VERSION ""

NS_ :

BS_:

BU_: BMS

BO_ 663 BMS_HSC1_FrP02: 8 BMS
 SG_ BMSMainRelaySts_h1HSC1 : 54|2@0+ (1,0) [0|3] "" Vector__XXX

BO_ 667 BMS_HSC1_FrP07: 8 BMS
 SG_ BMSChrgrPlugCnctnIO_h1HSC1 : 6|1@0+ (1,0) [0|1] "" Vector__XXX
 SG_ BMSChrgStsIO_h1HSC1 : 7|1@0+ (1,0) [0|1] "" Vector__XXX

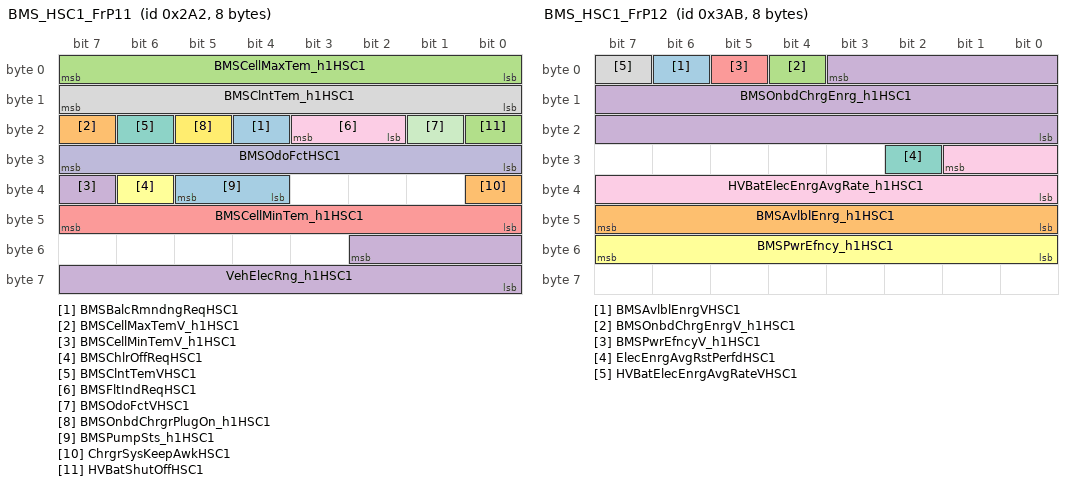
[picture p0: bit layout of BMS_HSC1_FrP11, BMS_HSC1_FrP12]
BO_ 674 BMS_HSC1_FrP11: 8 BMS
 SG_ BMSBalcRmndngReqHSC1 : 20|1@0+ (1,0) [0|1] "" Vector__XXX
 SG_ BMSCellMaxTemV_h1HSC1 : 23|1@0+ (1,0) [0|1] "" Vector__XXX
 SG_ BMSCellMaxTem_h1HSC1 : 7|8@0+ (0.5,-40) [-40|87.5] "DegC" Vector__XXX
 SG_ BMSCellMinTemV_h1HSC1 : 39|1@0+ (1,0) [0|1] "" Vector__XXX
 SG_ BMSCellMinTem_h1HSC1 : 47|8@0+ (0.5,-40) [-40|87.5] "Deg C" Vector__XXX
 SG_ BMSChlrOffReqHSC1 : 38|1@0+ (1,0) [0|1] "" Vector__XXX
 SG_ BMSClntTemVHSC1 : 22|1@0+ (1,0) [0|1] "" Vector__XXX
 SG_ BMSClntTem_h1HSC1 : 15|8@0+ (0.5,-40) [-40|87.5] "degC" Vector__XXX
 SG_ BMSFltIndReqHSC1 : 19|2@0+ (1,0) [0|3] "" Vector__XXX
 SG_ BMSOdoFctHSC1 : 31|8@0+ (0.5,0) [0|127.5] "%" Vector__XXX
 SG_ BMSOdoFctVHSC1 : 17|1@0+ (1,0) [0|1] "" Vector__XXX
 SG_ BMSOnbdChrgrPlugOn_h1HSC1 : 21|1@0+ (1,0) [0|1] "" Vector__XXX
 SG_ BMSPumpSts_h1HSC1 : 37|2@0+ (1,0) [0|3] "" Vector__XXX
 SG_ ChrgrSysKeepAwkHSC1 : 32|1@0+ (1,0) [0|1] "" Vector__XXX
 SG_ HVBatShutOffHSC1 : 16|1@0+ (1,0) [0|1] "" Vector__XXX
 SG_ VehElecRng_h1HSC1 : 50|11@0+ (1,0) [0|2047] "km" Vector__XXX

BO_ 939 BMS_HSC1_FrP12: 8 BMS
 SG_ BMSAvlblEnrgVHSC1 : 6|1@0+ (1,0) [0|1] "" Vector__XXX
 SG_ BMSAvlblEnrg_h1HSC1 : 47|8@0+ (0.1,0) [0|25.5] "kWh" Vector__XXX
 SG_ BMSOnbdChrgEnrgV_h1HSC1 : 4|1@0+ (1,0) [0|1] "" Vector__XXX
 SG_ BMSOnbdChrgEnrg_h1HSC1 : 3|20@0+ (0.1,0) [0|104857] "" Vector__XXX
 SG_ BMSPwrEfncyV_h1HSC1 : 5|1@0+ (1,0) [0|1] "" Vector__XXX
 SG_ BMSPwrEfncy_h1HSC1 : 55|8@0+ (0.5,0) [0|126.5] "" Vector__XXX
 SG_ ElecEnrgAvgRstPerfdHSC1 : 26|1@0+ (1,0) [0|1] "" Vector__XXX
 SG_ HVBatElecEnrgAvgRateVHSC1 : 7|1@0+ (1,0) [0|1] "" Vector__XXX
 SG_ HVBatElecEnrgAvgRate_h1HSC1 : 25|10@0+ (0.1,-20) [-20|82.3] "" Vector__XXX

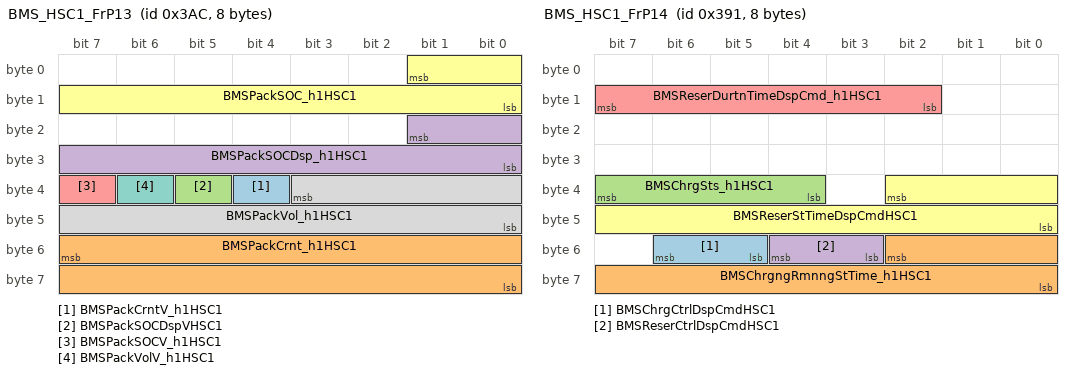
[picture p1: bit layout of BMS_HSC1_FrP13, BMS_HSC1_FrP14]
BO_ 940 BMS_HSC1_FrP13: 8 BMS
 SG_ BMSPackCrntV_h1HSC1 : 36|1@0+ (1,0) [0|1] "" Vector__XXX
 SG_ BMSPackCrnt_h1HSC1 : 55|16@0+ (0.025,-1000) [-1000|638.375] "A" Vector__XXX
 SG_ BMSPackSOCDspVHSC1 : 37|1@0+ (1,0) [0|1] "" Vector__XXX
 SG_ BMSPackSOCDsp_h1HSC1 : 17|10@0+ (0.1,0) [0|102.3] "" Vector__XXX
 SG_ BMSPackSOCV_h1HSC1 : 39|1@0+ (1,0) [0|1] "" Vector__XXX
 SG_ BMSPackSOC_h1HSC1 : 1|10@0+ (0.1,0) [0|102.3] "%" Vector__XXX
 SG_ BMSPackVolV_h1HSC1 : 38|1@0+ (1,0) [0|1] "" Vector__XXX
 SG_ BMSPackVol_h1HSC1 : 35|12@0+ (0.25,0) [0|1023.75] "V" Vector__XXX

BO_ 913 BMS_HSC1_FrP14: 8 BMS
 SG_ BMSChrgCtrlDspCmdHSC1 : 54|2@0+ (1,0) [0|3] "" Vector__XXX
 SG_ BMSChrgngRmnngStTime_h1HSC1 : 50|11@0+ (1,0) [0|1500] "minute" Vector__XXX
 SG_ BMSChrgSts_h1HSC1 : 39|4@0+ (1,0) [0|15] "" Vector__XXX
 SG_ BMSReserCtrlDspCmdHSC1 : 52|2@0+ (1,0) [0|3] "" Vector__XXX
 SG_ BMSReserDurtnTimeDspCmd_h1HSC1 : 15|6@0+ (0.5,0) [0|20] "" Vector__XXX
 SG_ BMSReserStTimeDspCmdHSC1 : 34|11@0+ (1,0) [0|2047] "" Vector__XXX

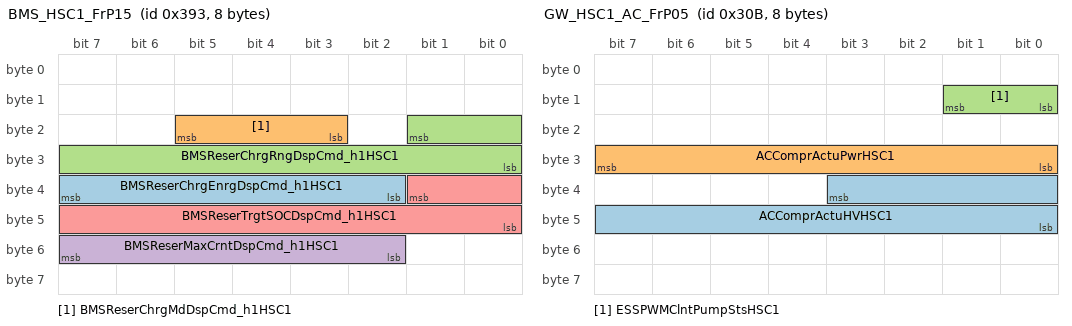
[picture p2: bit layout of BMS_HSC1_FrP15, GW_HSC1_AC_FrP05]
BO_ 915 BMS_HSC1_FrP15: 8 BMS
 SG_ BMSReserChrgEnrgDspCmd_h1HSC1 : 39|6@0+ (1,0) [0|63] "" Vector__XXX
 SG_ BMSReserChrgMdDspCmd_h1HSC1 : 21|3@0+ (1,0) [0|7] "" Vector__XXX
 SG_ BMSReserChrgRngDspCmd_h1HSC1 : 17|10@0+ (1,0) [0|1023] "" Vector__XXX
 SG_ BMSReserMaxCrntDspCmd_h1HSC1 : 55|6@0+ (1,0) [0|32] "" Vector__XXX
 SG_ BMSReserTrgtSOCDspCmd_h1HSC1 : 33|10@0+ (0.1,0) [0|102.3] "" Vector__XXX

BO_ 936 BMS_HSC1_FrP16: 8 BMS
 SG_ ChrgngRmnngTimeV_h1HSC1 : 54|1@0+ (1,0) [0|1] "" Vector__XXX
 SG_ ChrgngRmnngTime_h1HSC1 : 31|10@0+ (1,0) [0|1023] "minute" Vector__XXX

BO_ 1288 BMS_HSC1_FrP18: 8 BMS
 SG_ BMSEmsnRltdMalfAHSC1 : 7|1@0+ (1,0) [0|1] "" Vector__XXX

BO_ 1803 DIAG_DTCInfo_BMS: 7 BMS
 SG_ DTCInfomationBMSHSC1 : 7|56@0+ (1,0) [0|0] "" Vector__XXX

BO_ 2015 DIAG_FuncReq_HSC1: 8 Vector__XXX
 SG_ DiagnosticFuncAddrReq : 7|64@0+ (1,0) [0|0] ""  BMS

BO_ 1921 DIAG_PhysReq_BMS: 8 Vector__XXX
 SG_ DiagnosticReqBMS_h1 : 7|64@0+ (1,0) [0|0] ""  BMS

BO_ 1929 DIAG_PhysResp_BMS: 8 BMS
 SG_ DiagnosticRespBMS : 7|64@0+ (1,0) [0|0] "" Vector__XXX

BO_ 201 ECM_HSC1_FrP00: 8 Vector__XXX
 SG_ EnRunAHSC1 : 7|1@0+ (1,0) [0|1] ""  BMS
 SG_ EnSpdHSC1 : 15|16@0+ (0.25,0) [0|16383.8] "rpm"  BMS

BO_ 404 ECM_HSC1_FrP04: 8 Vector__XXX
 SG_ TrShftLvrPosHSC1 : 27|4@0+ (1,0) [0|15] ""  BMS
 SG_ TrShftLvrPosVHSC1 : 28|1@0+ (1,0) [0|1] ""  BMS

BO_ 1217 ECM_HSC1_FrP14: 8 Vector__XXX
 SG_ EnClntTemHSC1 : 23|8@0+ (1,-40) [-40|215] "deg C"  BMS
 SG_ EnClntTemVHSC1 : 6|1@0+ (1,0) [0|1] ""  BMS

BO_ 889 GW_HSC1_AC_FrP02: 8 Vector__XXX
 SG_ ACAmbtTemHSC1 : 7|8@0+ (0.5,-40) [-40|87.5] "deg C"  BMS
 SG_ ACAmbtTemVHSC1 : 39|1@0+ (1,0) [0|1] ""  BMS

BO_ 868 GW_HSC1_AC_FrP03: 8 Vector__XXX
 SG_ ACComprReqHSC1 : 17|2@0+ (1,0) [0|3] ""  BMS
 SG_ HVBatCoolngSysEnbdHSC1 : 55|1@0+ (1,0) [0|1] ""  BMS

BO_ 779 GW_HSC1_AC_FrP05: 8 Vector__XXX
 SG_ ACComprActuHVHSC1 : 35|12@0+ (0.25,0) [0|1023.25] ""  BMS
 SG_ ACComprActuPwrHSC1 : 31|8@0+ (0.03,0) [0|7.65] "Kw"  BMS
 SG_ ESSPWMClntPumpStsHSC1 : 9|2@0+ (1,0) [0|3] ""  BMS

BO_ 1130 GW_HSC1_BCM_FrP04: 8 Vector__XXX
 SG_ BntOpenStsHSC1 : 47|2@0+ (1,0) [0|3] ""  BMS
 SG_ VehLckngStaHSC1 : 22|3@0+ (1,0) [0|7] ""  BMS

BO_ 540 GW_HSC1_BCM_FrP06: 8 Vector__XXX
 SG_ RVSReqHSC1 : 34|1@0+ (1,0) [0|1] ""  BMS

BO_ 498 GW_HSC1_BCM_FrP07: 2 Vector__XXX
 SG_ SysBPMHSC1 : 5|2@0+ (1,0) [0|3] ""  BMS
 SG_ SysBPMEnbdHSC1 : 6|1@0+ (1,0) [0|1] ""  BMS

BO_ 886 GW_HSC1_FICM_FrP02: 8 Vector__XXX
 SG_ RstrFctryDeftsReqHSC1 : 56|1@0+ (1,0) [0|1] ""  BMS

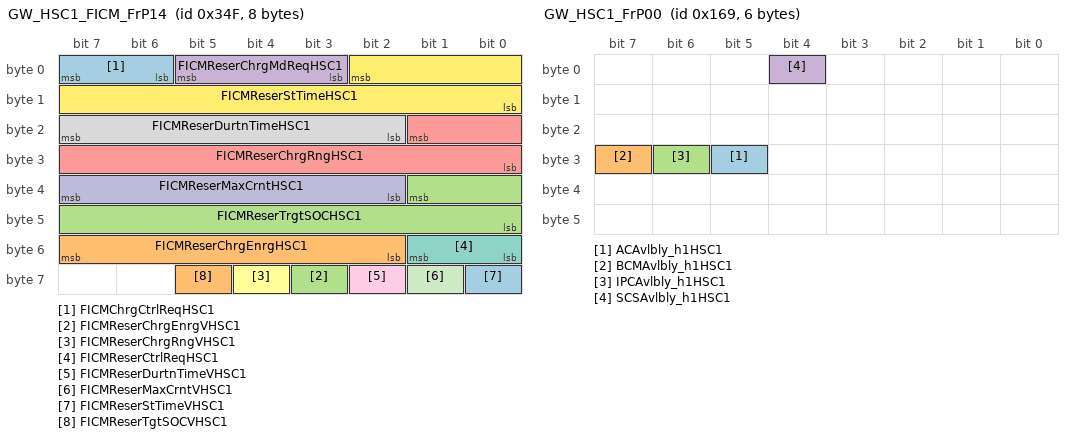
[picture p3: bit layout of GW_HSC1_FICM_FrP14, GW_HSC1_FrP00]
BO_ 847 GW_HSC1_FICM_FrP14: 8 Vector__XXX
 SG_ FICMChrgCtrlReqHSC1 : 7|2@0+ (1,0) [0|3] ""  BMS
 SG_ FICMReserChrgEnrgHSC1 : 55|6@0+ (1,0) [0|63] ""  BMS
 SG_ FICMReserChrgEnrgVHSC1 : 59|1@0+ (1,0) [0|1] ""  BMS
 SG_ FICMReserChrgMdReqHSC1 : 5|3@0+ (1,0) [0|7] ""  BMS
 SG_ FICMReserChrgRngHSC1 : 17|10@0+ (1,0) [0|1023] ""  BMS
 SG_ FICMReserChrgRngVHSC1 : 60|1@0+ (1,0) [0|1] ""  BMS
 SG_ FICMReserCtrlReqHSC1 : 49|2@0+ (1,0) [0|3] ""  BMS
 SG_ FICMReserDurtnTimeHSC1 : 23|6@0+ (0.5,0) [0|20] ""  BMS
 SG_ FICMReserDurtnTimeVHSC1 : 58|1@0+ (1,0) [0|1] ""  BMS
 SG_ FICMReserMaxCrntHSC1 : 39|6@0+ (1,0) [0|32] ""  BMS
 SG_ FICMReserMaxCrntVHSC1 : 57|1@0+ (1,0) [0|1] ""  BMS
 SG_ FICMReserStTimeHSC1 : 2|11@0+ (1,0) [0|2047] ""  BMS
 SG_ FICMReserStTimeVHSC1 : 56|1@0+ (1,0) [0|1] ""  BMS
 SG_ FICMReserTgtSOCVHSC1 : 61|1@0+ (1,0) [0|1] ""  BMS
 SG_ FICMReserTrgtSOCHSC1 : 33|10@0+ (0.1,0) [0|102.3] ""  BMS

BO_ 361 GW_HSC1_FrP00: 6 Vector__XXX
 SG_ ACAvlbly_h1HSC1 : 29|1@0+ (1,0) [0|1] ""  BMS
 SG_ BCMAvlbly_h1HSC1 : 31|1@0+ (1,0) [0|1] ""  BMS
 SG_ IPCAvlbly_h1HSC1 : 30|1@0+ (1,0) [0|1] ""  BMS
 SG_ SCSAvlbly_h1HSC1 : 4|1@0+ (1,0) [0|1] ""  BMS

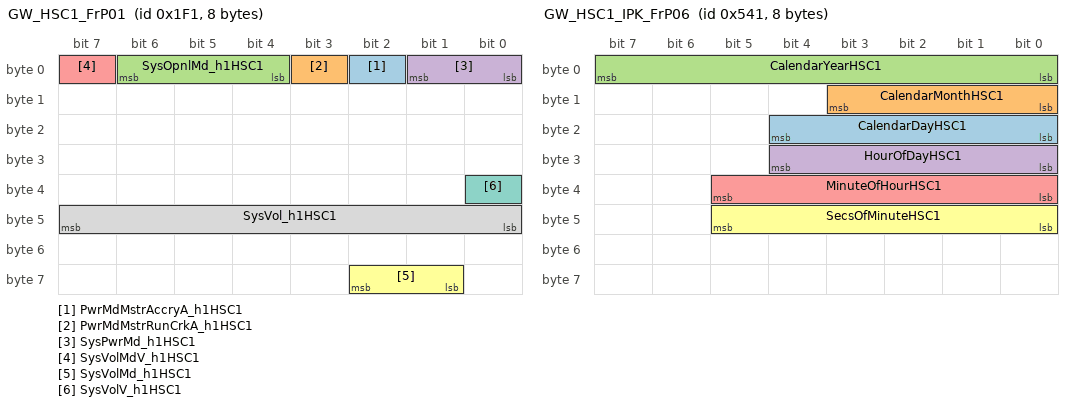
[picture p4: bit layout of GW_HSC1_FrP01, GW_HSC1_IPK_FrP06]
BO_ 497 GW_HSC1_FrP01: 8 Vector__XXX
 SG_ PwrMdMstrAccryA_h1HSC1 : 2|1@0+ (1,0) [0|1] ""  BMS
 SG_ PwrMdMstrRunCrkA_h1HSC1 : 3|1@0+ (1,0) [0|1] ""  BMS
 SG_ SysOpnlMd_h1HSC1 : 6|3@0+ (1,0) [0|7] ""  BMS
 SG_ SysPwrMd_h1HSC1 : 1|2@0+ (1,0) [0|3] ""  BMS
 SG_ SysVolMdV_h1HSC1 : 7|1@0+ (1,0) [0|1] ""  BMS
 SG_ SysVolMd_h1HSC1 : 58|2@0+ (1,0) [0|3] ""  BMS
 SG_ SysVolV_h1HSC1 : 32|1@0+ (1,0) [0|1] ""  BMS
 SG_ SysVol_h1HSC1 : 47|8@0+ (0.1,3) [3|28.5] "V"  BMS

BO_ 1344 GW_HSC1_FrP07: 8 Vector__XXX
 SG_ VehOdoV_h1HSC1 : 31|1@0+ (1,0) [0|1] ""  BMS
 SG_ VehOdo_h1HSC1 : 7|24@0+ (1,0) [0|16777200] ""  BMS

BO_ 1009 GW_HSC1_FrP10: 8 Vector__XXX
 SG_ OtsdAirTemCrValV_h1HSC1 : 48|1@0+ (1,0) [0|1] ""  BMS
 SG_ OtsdAirTemCrVal_h1HSC1 : 63|8@0+ (0.5,-40) [-40|87.5] "deg C"  BMS

BO_ 1345 GW_HSC1_IPK_FrP06: 8 Vector__XXX
 SG_ CalendarDayHSC1 : 20|5@0+ (1,0) [0|31] "day"  BMS
 SG_ CalendarMonthHSC1 : 11|4@0+ (1,0) [0|15] ""  BMS
 SG_ CalendarYearHSC1 : 7|8@0+ (1,2000) [2000|2255] "year"  BMS
 SG_ HourOfDayHSC1 : 28|5@0+ (1,0) [0|23] ""  BMS
 SG_ MinuteOfHourHSC1 : 37|6@0+ (1,0) [0|59] ""  BMS
 SG_ SecsOfMinuteHSC1 : 45|6@0+ (1,0) [0|59] ""  BMS

BO_ 835 GW_HSC1_IPK_FrP10: 8 Vector__XXX
 SG_ ElecEnrgAvgRstReqHSC1 : 7|1@0+ (1,0) [0|1] ""  BMS

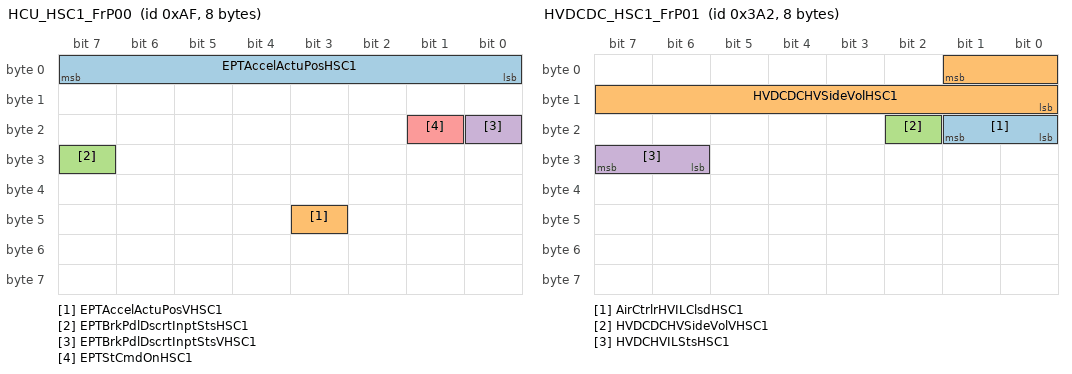
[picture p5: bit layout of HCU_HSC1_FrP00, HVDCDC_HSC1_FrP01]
BO_ 175 HCU_HSC1_FrP00: 8 Vector__XXX
 SG_ EPTAccelActuPosHSC1 : 7|8@0+ (0.392157,0) [0|100] "%"  BMS
 SG_ EPTAccelActuPosVHSC1 : 43|1@0+ (1,0) [0|1] ""  BMS
 SG_ EPTBrkPdlDscrtInptStsHSC1 : 31|1@0+ (1,0) [0|1] ""  BMS
 SG_ EPTBrkPdlDscrtInptStsVHSC1 : 16|1@0+ (1,0) [0|1] ""  BMS
 SG_ EPTStCmdOnHSC1 : 17|1@0+ (1,0) [0|1] ""  BMS

BO_ 406 HCU_HSC1_FrP01: 8 Vector__XXX
 SG_ EPTRdyHSC1 : 38|1@0+ (1,0) [0|1] ""  BMS

BO_ 907 HCU_HSC1_FrP07: 8 Vector__XXX
 SG_ ElecVehSysMdHSC1 : 55|4@0+ (1,0) [0|15] ""  BMS
 SG_ EPTDrvngMdSwStsHSC1 : 18|3@0+ (1,0) [0|7] ""  BMS

BO_ 930 HVDCDC_HSC1_FrP01: 8 Vector__XXX
 SG_ AirCtrlrHVILClsdHSC1 : 17|2@0+ (1,0) [0|3] ""  BMS
 SG_ HVDCDCHVSideVolHSC1 : 1|10@0+ (1,0) [0|1023] "V"  BMS
 SG_ HVDCDCHVSideVolVHSC1 : 18|1@0+ (1,0) [0|1] ""  BMS
 SG_ HVDCHVILStsHSC1 : 31|2@0+ (1,0) [0|3] ""  BMS

BO_ 147 ISC_HSC1_FrP03: 8 Vector__XXX
 SG_ ISGSpd_h1HSC1 : 23|16@0+ (1,-32768) [-32768|32767] "rpm"  BMS

BO_ 851 SCS_HSC1_FrP15: 8 Vector__XXX
 SG_ VehSpdAvgDrvnV_h1HSC1 : 7|1@0+ (1,0) [0|1] ""  BMS
 SG_ VehSpdAvgDrvn_h1HSC1 : 6|15@0+ (0.015625,0) [0|511.984] "km/h"  BMS

BO_ 355 SDM_HSC1_FrP00: 8 Vector__XXX
 SG_ AirbagDplHSC1 : 11|1@0+ (1,0) [0|1] ""  BMS

CM_ SG_ 663 BMSMainRelaySts_h1HSC1 "Battery Management System Main Relay Status";
CM_ SG_ 667 BMSChrgrPlugCnctnIO_h1HSC1 "Battery Management System Charger Plug Connection Indication On";
CM_ SG_ 667 BMSChrgStsIO_h1HSC1 "Battery Management System Charge Status Indication On";
CM_ SG_ 674 BMSBalcRmndngReqHSC1 "Battery Management System Balance Reminding Request
";
CM_ SG_ 674 BMSCellMaxTemV_h1HSC1 "Battery Management System Cell Maximum Temperature Validity
";
CM_ SG_ 674 BMSCellMaxTem_h1HSC1 "Battery Management System Cell Maximum Temperature
";
CM_ SG_ 674 BMSCellMinTemV_h1HSC1 "Battery Management System Cell Minimum Temperature Validity";
CM_ SG_ 674 BMSCellMinTem_h1HSC1 "Battery Management System Cell Minimum Temperature";
CM_ SG_ 674 BMSChlrOffReqHSC1 "Battery Management System Chiller Off Request";
CM_ SG_ 674 BMSClntTemVHSC1 "Battery Management System Coolant Temperature Validity";
CM_ SG_ 674 BMSClntTem_h1HSC1 "Battery Management System Coolant Temperature";
CM_ SG_ 674 BMSFltIndReqHSC1 "Battery Management System Fault Indication Request
";
CM_ SG_ 674 BMSOdoFctHSC1 "Battery Management System Odometer Factor
";
CM_ SG_ 674 BMSOdoFctVHSC1 "Battery Management System Odometer Factor Validity
";
CM_ SG_ 674 BMSOnbdChrgrPlugOn_h1HSC1 "Battery Management System Onboard Charger Plug On";
CM_ SG_ 674 BMSPumpSts_h1HSC1 "Battery Management System Pump Status";
CM_ SG_ 674 ChrgrSysKeepAwkHSC1 "Charger System Keep Awake";
CM_ SG_ 674 HVBatShutOffHSC1 "High Voltage Battery Shut Off";
CM_ SG_ 674 VehElecRng_h1HSC1 "Vehicle Electric Range";
CM_ SG_ 939 BMSAvlblEnrgVHSC1 "Battery Management System Available Energy Validity";
CM_ SG_ 939 BMSAvlblEnrg_h1HSC1 "Battery Management System Available Energy";
CM_ SG_ 939 BMSOnbdChrgEnrgV_h1HSC1 "Battery Management System Onboard Charge Energy Validity
";
CM_ SG_ 939 BMSOnbdChrgEnrg_h1HSC1 "Battery Management System Onboard Charge Energy
";
CM_ SG_ 939 BMSPwrEfncyV_h1HSC1 "Battery Management System Power Efficiency Validity";
CM_ SG_ 939 BMSPwrEfncy_h1HSC1 "Battery Management System Power Efficiency";
CM_ SG_ 939 ElecEnrgAvgRstPerfdHSC1 "Electric Energy Average Reset Performed";
CM_ SG_ 939 HVBatElecEnrgAvgRateVHSC1 "High Voltage Battery Electric Energy Average Rate Validity";
CM_ SG_ 939 HVBatElecEnrgAvgRate_h1HSC1 "High Voltage Battery Electric Energy Average Rate";
CM_ SG_ 940 BMSPackCrntV_h1HSC1 "Battery Management System Pack Current Validity";
CM_ SG_ 940 BMSPackCrnt_h1HSC1 "Battery Management System Pack Current";
CM_ SG_ 940 BMSPackSOCDspVHSC1 "Battery Management System Pack State Of Charge Display Validity";
CM_ SG_ 940 BMSPackSOCDsp_h1HSC1 "SOC displayed for customer";
CM_ SG_ 940 BMSPackSOCV_h1HSC1 "Battery Management System Pack State Of Charge Validity
";
CM_ SG_ 940 BMSPackSOC_h1HSC1 "Battery Management System Pack State Of Charge
";
CM_ SG_ 940 BMSPackVolV_h1HSC1 "Battery Management System Pack Voltage Validity";
CM_ SG_ 940 BMSPackVol_h1HSC1 "Battery Management System Pack Voltage";
CM_ SG_ 913 BMSChrgCtrlDspCmdHSC1 "Battery Management System Charge Control Display Command";
CM_ SG_ 913 BMSChrgngRmnngStTime_h1HSC1 "Battery Management System Charging Remain Start Time";
CM_ SG_ 913 BMSChrgSts_h1HSC1 "Battery Management System Charge Status";
CM_ SG_ 913 BMSReserCtrlDspCmdHSC1 "Battery Management System Reservation Control Display Command";
CM_ SG_ 913 BMSReserDurtnTimeDspCmd_h1HSC1 "Battery Management System Reservation Duration Time Display Command";
CM_ SG_ 913 BMSReserStTimeDspCmdHSC1 "Battery Management System Reservation Start Time Display Command";
CM_ SG_ 915 BMSReserChrgEnrgDspCmd_h1HSC1 "Battery Management System Reservation Charge Energy Display Command";
CM_ SG_ 915 BMSReserChrgMdDspCmd_h1HSC1 "Battery Management System Reservation Charge Mode Display Command";
CM_ SG_ 915 BMSReserChrgRngDspCmd_h1HSC1 "Battery Management System Reservation Charge Range Display Command";
CM_ SG_ 915 BMSReserMaxCrntDspCmd_h1HSC1 "Battery Management System Reservation Maximun Current Display Command";
CM_ SG_ 915 BMSReserTrgtSOCDspCmd_h1HSC1 "Battery Management System Reservaion Target Soc Display Command";
CM_ SG_ 936 ChrgngRmnngTimeV_h1HSC1 "Charging Remaining Time Validity";
CM_ SG_ 936 ChrgngRmnngTime_h1HSC1 "Charging Remaining Time";
CM_ SG_ 1288 BMSEmsnRltdMalfAHSC1 "Battery Management System Emissions Related Malfunction Active";
CM_ SG_ 2015 DiagnosticFuncAddrReq "Diagnostic functional address request";
CM_ SG_ 1921 DiagnosticReqBMS_h1 "Diagnostic request to BMS";
CM_ SG_ 1929 DiagnosticRespBMS "Diagnostic response from BMS";
CM_ SG_ 201 EnRunAHSC1 "Engine Run Active";
CM_ SG_ 201 EnSpdHSC1 "Engine Speed";
CM_ SG_ 404 TrShftLvrPosHSC1 "Transmission Shift Lever Position

For DCT/AT transmission :
$0=Between Ranges
$1=Park Range
$2=Reverse Range
$3=Neutral Range
$4=Forward Range A
$5=Forward Range B
$6=Forward Range C
$7=Forward Range D
$8=Forward Range E
$9=Forward Range F
$A=Forward Range G
$B=Forward Range H
$F=Lever Position Unknown

For Manual Transmission: only below status are used
$2=Reverse Range
$3=Neutral Range (Validity on MT vehicles is only protected for Neutral range)
$F=Lever Position Unknown";
CM_ SG_ 404 TrShftLvrPosVHSC1 "Transmission Shift Lever Position Validity";
CM_ SG_ 1217 EnClntTemHSC1 "Engine Coolant Temperature";
CM_ SG_ 1217 EnClntTemVHSC1 "Engine Coolant Temperature Validity";
CM_ SG_ 889 ACAmbtTemHSC1 "Air Conditioning Ambient Temperature";
CM_ SG_ 889 ACAmbtTemVHSC1 "Air Conditioning Ambient Temperature Validity";
CM_ SG_ 868 ACComprReqHSC1 "Air Conditioning Compressor Request";
CM_ SG_ 868 HVBatCoolngSysEnbdHSC1 "High Voltage Battery Cooling System Enabled
";
CM_ SG_ 779 ACComprActuHVHSC1 "Air Conditioning Compressor Actual High Voltage
";
CM_ SG_ 779 ACComprActuPwrHSC1 "Air Conditioning Compressor Actual Power
";
CM_ SG_ 779 ESSPWMClntPumpStsHSC1 "Energy Storage System Pulse Width Modulation Coolant Pump Status";
CM_ SG_ 1130 BntOpenStsHSC1 "Bonnet Open Status";
CM_ SG_ 1130 VehLckngStaHSC1 "Vehicle Locking State";
CM_ SG_ 540 RVSReqHSC1 "Remote Vehicle Start Request";
CM_ SG_ 498 SysBPMHSC1 "System Backup Power Mode";
CM_ SG_ 498 SysBPMEnbdHSC1 "System Backup Power Mode Enabled";
CM_ SG_ 886 RstrFctryDeftsReqHSC1 "Restore Factory Defaults Request";
CM_ SG_ 847 FICMChrgCtrlReqHSC1 "Front Infotainment Control Module Charge Control Request";
CM_ SG_ 847 FICMReserChrgEnrgHSC1 "Front Infotainment Control Module Reservation Charge Energy";
CM_ SG_ 847 FICMReserChrgEnrgVHSC1 "Front Infotainment Control Module Reservation Charge Energy Validity";
CM_ SG_ 847 FICMReserChrgMdReqHSC1 "Front Infotainment Control Module Reservation Charge Mode Request";
CM_ SG_ 847 FICMReserChrgRngHSC1 "Front Infotainment Control Module Reservation Charge Range";
CM_ SG_ 847 FICMReserChrgRngVHSC1 "Front Infotainment Control Module Reservation Charge Range Validity";
CM_ SG_ 847 FICMReserCtrlReqHSC1 "Front Infotainment Control Module Reservation Control Request";
CM_ SG_ 847 FICMReserDurtnTimeHSC1 "Front Infotainment Control Module Reservation Duration Time";
CM_ SG_ 847 FICMReserDurtnTimeVHSC1 "Front Infotainment Control Module Reservation Duration Time Validity";
CM_ SG_ 847 FICMReserMaxCrntHSC1 "Front Infotainment Control Module Reservation Maximun Current Request";
CM_ SG_ 847 FICMReserMaxCrntVHSC1 "Front Infotainment Control Module Reservation Maximun Current Request Validity";
CM_ SG_ 847 FICMReserStTimeHSC1 "Front Infotainment Control Module Reservation Start Time";
CM_ SG_ 847 FICMReserStTimeVHSC1 "Front Infotainment Control Module Reservation Start Time Validity";
CM_ SG_ 847 FICMReserTgtSOCVHSC1 "Front Infotainment Control Module Reservation Target Soc Validity";
CM_ SG_ 847 FICMReserTrgtSOCHSC1 "Front Infotainment Control Module Reservation Target Soc";
CM_ SG_ 361 ACAvlbly_h1HSC1 "AC Available

Detect if specific ECU is available according to node missing strategy by gateway ECU.

";
CM_ SG_ 361 BCMAvlbly_h1HSC1 "BCM Available

Detect if specific ECU is available according to node missing strategy by gateway ECU.
";
CM_ SG_ 361 IPCAvlbly_h1HSC1 "IPK Available

Detect if specific ECU is available according to node missing strategy by gateway ECU.

";
CM_ SG_ 361 SCSAvlbly_h1HSC1 "SCS Available

Detect if specific ECU is available according to node missing strategy by gateway ECU.

";
CM_ SG_ 497 PwrMdMstrAccryA_h1HSC1 "Power Mode Master Accessory Terminal Status";
CM_ SG_ 497 PwrMdMstrRunCrkA_h1HSC1 "Power Mode Master Run Crank Terminal Status";
CM_ SG_ 497 SysOpnlMd_h1HSC1 "System Operational Mode";
CM_ SG_ 497 SysPwrMd_h1HSC1 "System Power Mode";
CM_ SG_ 497 SysVolMdV_h1HSC1 "System Voltage Mode Validity ";
CM_ SG_ 497 SysVolMd_h1HSC1 "System Voltage Mode ";
CM_ SG_ 497 SysVolV_h1HSC1 "Battery Voltage Validity";
CM_ SG_ 497 SysVol_h1HSC1 "Battery Voltage";
CM_ SG_ 1344 VehOdoV_h1HSC1 "Vehicle Odometer Validity";
CM_ SG_ 1344 VehOdo_h1HSC1 "Vehicle Odometer";
CM_ SG_ 1009 OtsdAirTemCrValV_h1HSC1 "Outside Air Temperature Corrected Value Validity";
CM_ SG_ 1009 OtsdAirTemCrVal_h1HSC1 "Outside Air Temperature Corrected Value";
CM_ SG_ 1345 CalendarDayHSC1 "current day info.";
CM_ SG_ 1345 CalendarMonthHSC1 "current month info.";
CM_ SG_ 1345 CalendarYearHSC1 "current year info";
CM_ SG_ 1345 HourOfDayHSC1 "Hour Of Day.
current Hour info.";
CM_ SG_ 1345 MinuteOfHourHSC1 "Minute Of Hour.
current Minute info.";
CM_ SG_ 1345 SecsOfMinuteHSC1 "Seconds Of Minute
current Second info.";
CM_ SG_ 835 ElecEnrgAvgRstReqHSC1 "Electric Energy Average Reset Request";
CM_ SG_ 175 EPTAccelActuPosHSC1 "Electric Powertrain Accelerator Actual Position";
CM_ SG_ 175 EPTAccelActuPosVHSC1 "Electric Powertrain Accelerator Actual Position Validity";
CM_ SG_ 175 EPTBrkPdlDscrtInptStsHSC1 "Electric Powertrain Brake Pedal Discrete Input Status";
CM_ SG_ 175 EPTBrkPdlDscrtInptStsVHSC1 "Electric Powertrain Brake Pedal Discrete Input Status Validity";
CM_ SG_ 175 EPTStCmdOnHSC1 "Electric Powertrain Start Command On";
CM_ SG_ 406 EPTRdyHSC1 "Electric Powertrain Ready";
CM_ SG_ 907 ElecVehSysMdHSC1 "Electric Vehicle System Mode
";
CM_ SG_ 907 EPTDrvngMdSwStsHSC1 "Electric Powertrain Driving Mode Switch Status";
CM_ SG_ 930 AirCtrlrHVILClsdHSC1 "Air Controller High Voltage Interlock Loop Closed";
CM_ SG_ 930 HVDCDCHVSideVolHSC1 "High Voltage Direct Current Direct Current High Voltage Side Voltage";
CM_ SG_ 930 HVDCDCHVSideVolVHSC1 "High Voltage Direct Current Direct Current High Voltage Side Voltage Validity";
CM_ SG_ 930 HVDCHVILStsHSC1 "High Voltage Direct Current High Voltage Interlock Loop Status";
CM_ SG_ 147 ISGSpd_h1HSC1 "Integrated Starter Generator Speed";
CM_ SG_ 851 VehSpdAvgDrvnV_h1HSC1 "Vehicle Speed Average Driven Validity";
CM_ SG_ 851 VehSpdAvgDrvn_h1HSC1 "Vehicle Speed Average Driven";
CM_ SG_ 355 AirbagDplHSC1 "Airbag Deployed";
BA_DEF_  "BusType" STRING ;
BA_DEF_ SG_  "GenSigLongName" STRING ;
BA_DEF_ SG_  "GenSigStartValue" INT -9.22337203685478E+018 1.84467440737096E+019;
BA_DEF_ BO_  "GenMsgDelayTime" FLOAT 0 300000;
BA_DEF_ BO_  "GenMsgCycleTime" FLOAT 0 300000;
BA_DEF_ BO_  "GenMsgSendType" ENUM  "cyclic","spontaneous","cyclicIfActive","spontaneousWithDelay","immediate";
BA_DEF_DEF_  "BusType" "";
BA_DEF_DEF_  "GenSigLongName" "";
BA_DEF_DEF_  "GenSigStartValue" 0;
BA_DEF_DEF_  "GenMsgDelayTime" 0;
BA_DEF_DEF_  "GenMsgCycleTime" 0;
BA_DEF_DEF_  "GenMsgSendType" "";
BA_ "BusType" "CAN";
BA_ "GenMsgCycleTime" BO_ 663 50;
BA_ "GenMsgSendType" BO_ 663 0;
BA_ "GenMsgCycleTime" BO_ 667 50;
BA_ "GenMsgSendType" BO_ 667 0;
BA_ "GenMsgCycleTime" BO_ 674 100;
BA_ "GenMsgSendType" BO_ 674 0;
BA_ "GenMsgCycleTime" BO_ 939 100;
BA_ "GenMsgSendType" BO_ 939 0;
BA_ "GenMsgCycleTime" BO_ 940 100;
BA_ "GenMsgSendType" BO_ 940 0;
BA_ "GenMsgCycleTime" BO_ 913 100;
BA_ "GenMsgSendType" BO_ 913 0;
BA_ "GenMsgCycleTime" BO_ 915 100;
BA_ "GenMsgSendType" BO_ 915 0;
BA_ "GenMsgCycleTime" BO_ 936 100;
BA_ "GenMsgSendType" BO_ 936 0;
BA_ "GenMsgCycleTime" BO_ 1288 500;
BA_ "GenMsgSendType" BO_ 1288 0;
BA_ "GenMsgSendType" BO_ 1803 1;
BA_ "GenMsgSendType" BO_ 2015 4;
BA_ "GenMsgSendType" BO_ 1921 4;
BA_ "GenMsgSendType" BO_ 1929 4;
BA_ "GenMsgCycleTime" BO_ 201 10;
BA_ "GenMsgSendType" BO_ 201 0;
BA_ "GenMsgCycleTime" BO_ 404 25;
BA_ "GenMsgSendType" BO_ 404 0;
BA_ "GenMsgCycleTime" BO_ 1217 500;
BA_ "GenMsgSendType" BO_ 1217 0;
BA_ "GenMsgCycleTime" BO_ 889 100;
BA_ "GenMsgSendType" BO_ 889 0;
BA_ "GenMsgCycleTime" BO_ 868 100;
BA_ "GenMsgSendType" BO_ 868 0;
BA_ "GenMsgCycleTime" BO_ 779 100;
BA_ "GenMsgSendType" BO_ 779 0;
BA_ "GenMsgCycleTime" BO_ 1130 50;
BA_ "GenMsgSendType" BO_ 1130 0;
BA_ "GenMsgCycleTime" BO_ 540 50;
BA_ "GenMsgSendType" BO_ 540 0;
BA_ "GenMsgCycleTime" BO_ 498 20;
BA_ "GenMsgSendType" BO_ 498 0;
BA_ "GenMsgCycleTime" BO_ 886 100;
BA_ "GenMsgSendType" BO_ 886 0;
BA_ "GenMsgCycleTime" BO_ 847 100;
BA_ "GenMsgSendType" BO_ 847 0;
BA_ "GenMsgCycleTime" BO_ 361 20;
BA_ "GenMsgSendType" BO_ 361 0;
BA_ "GenMsgCycleTime" BO_ 497 20;
BA_ "GenMsgSendType" BO_ 497 0;
BA_ "GenMsgCycleTime" BO_ 1344 1000;
BA_ "GenMsgSendType" BO_ 1344 0;
BA_ "GenMsgCycleTime" BO_ 1009 250;
BA_ "GenMsgSendType" BO_ 1009 0;
BA_ "GenMsgCycleTime" BO_ 1345 200;
BA_ "GenMsgSendType" BO_ 1345 0;
BA_ "GenMsgCycleTime" BO_ 835 100;
BA_ "GenMsgSendType" BO_ 835 0;
BA_ "GenMsgCycleTime" BO_ 175 10;
BA_ "GenMsgSendType" BO_ 175 0;
BA_ "GenMsgCycleTime" BO_ 406 20;
BA_ "GenMsgSendType" BO_ 406 0;
BA_ "GenMsgCycleTime" BO_ 907 100;
BA_ "GenMsgSendType" BO_ 907 0;
BA_ "GenMsgCycleTime" BO_ 930 100;
BA_ "GenMsgSendType" BO_ 930 0;
BA_ "GenMsgCycleTime" BO_ 147 10;
BA_ "GenMsgSendType" BO_ 147 0;
BA_ "GenMsgCycleTime" BO_ 851 100;
BA_ "GenMsgSendType" BO_ 851 0;
BA_ "GenMsgCycleTime" BO_ 355 20;
BA_ "GenMsgSendType" BO_ 355 0;
BA_ "GenSigStartValue" SG_ 667 BMSChrgrPlugCnctnIO_h1HSC1 1;
BA_ "GenSigStartValue" SG_ 667 BMSChrgStsIO_h1HSC1 1;
BA_ "GenSigStartValue" SG_ 674 BMSCellMaxTemV_h1HSC1 1;
BA_ "GenSigStartValue" SG_ 674 BMSCellMaxTem_h1HSC1 255;
BA_ "GenSigStartValue" SG_ 674 BMSCellMinTemV_h1HSC1 1;
BA_ "GenSigStartValue" SG_ 674 BMSCellMinTem_h1HSC1 255;
BA_ "GenSigStartValue" SG_ 674 BMSClntTemVHSC1 1;
BA_ "GenSigStartValue" SG_ 674 BMSClntTem_h1HSC1 255;
BA_ "GenSigStartValue" SG_ 674 HVBatShutOffHSC1 1;
BA_ "GenSigStartValue" SG_ 674 VehElecRng_h1HSC1 2046;
BA_ "GenSigStartValue" SG_ 939 BMSOnbdChrgEnrg_h1HSC1 1048575;
BA_ "GenSigStartValue" SG_ 939 BMSPwrEfncy_h1HSC1 255;
BA_ "GenSigStartValue" SG_ 939 HVBatElecEnrgAvgRateVHSC1 1;
BA_ "GenSigStartValue" SG_ 939 HVBatElecEnrgAvgRate_h1HSC1 1023;
BA_ "GenSigStartValue" SG_ 940 BMSPackCrntV_h1HSC1 1;
BA_ "GenSigStartValue" SG_ 940 BMSPackCrnt_h1HSC1 65535;
BA_ "GenSigStartValue" SG_ 940 BMSPackSOCDsp_h1HSC1 1023;
BA_ "GenSigStartValue" SG_ 940 BMSPackSOCV_h1HSC1 1;
BA_ "GenSigStartValue" SG_ 940 BMSPackSOC_h1HSC1 1023;
BA_ "GenSigStartValue" SG_ 940 BMSPackVolV_h1HSC1 1;
BA_ "GenSigStartValue" SG_ 940 BMSPackVol_h1HSC1 4095;
BA_ "GenSigStartValue" SG_ 913 BMSChrgngRmnngStTime_h1HSC1 2046;
BA_ "GenSigStartValue" SG_ 913 BMSReserDurtnTimeDspCmd_h1HSC1 62;
BA_ "GenSigStartValue" SG_ 913 BMSReserStTimeDspCmdHSC1 2046;
BA_ "GenSigStartValue" SG_ 915 BMSReserChrgEnrgDspCmd_h1HSC1 62;
BA_ "GenSigStartValue" SG_ 915 BMSReserChrgRngDspCmd_h1HSC1 1022;
BA_ "GenSigStartValue" SG_ 915 BMSReserMaxCrntDspCmd_h1HSC1 62;
BA_ "GenSigStartValue" SG_ 915 BMSReserTrgtSOCDspCmd_h1HSC1 1022;
BA_ "GenSigStartValue" SG_ 936 ChrgngRmnngTimeV_h1HSC1 1;
BA_ "GenSigStartValue" SG_ 936 ChrgngRmnngTime_h1HSC1 1023;
BA_ "GenSigLongName" SG_ 1288 BMSEmsnRltdMalfAHSC1 "Battery Management System Emissions Related Malfunction Active";
BA_ "GenSigStartValue" SG_ 889 ACAmbtTemVHSC1 1;
BA_ "GenSigStartValue" SG_ 1130 VehLckngStaHSC1 7;
BA_ "GenSigStartValue" SG_ 847 FICMReserChrgEnrgHSC1 63;
BA_ "GenSigStartValue" SG_ 847 FICMReserChrgEnrgVHSC1 1;
BA_ "GenSigStartValue" SG_ 847 FICMReserChrgRngHSC1 1023;
BA_ "GenSigStartValue" SG_ 847 FICMReserChrgRngVHSC1 1;
BA_ "GenSigStartValue" SG_ 847 FICMReserDurtnTimeHSC1 63;
BA_ "GenSigStartValue" SG_ 847 FICMReserDurtnTimeVHSC1 1;
BA_ "GenSigStartValue" SG_ 847 FICMReserMaxCrntHSC1 63;
BA_ "GenSigStartValue" SG_ 847 FICMReserMaxCrntVHSC1 1;
BA_ "GenSigStartValue" SG_ 847 FICMReserStTimeHSC1 2047;
BA_ "GenSigStartValue" SG_ 847 FICMReserStTimeVHSC1 1;
BA_ "GenSigStartValue" SG_ 847 FICMReserTgtSOCVHSC1 1;
BA_ "GenSigStartValue" SG_ 847 FICMReserTrgtSOCHSC1 1023;
BA_ "GenSigStartValue" SG_ 175 EPTBrkPdlDscrtInptStsVHSC1 1;
BA_ "GenSigLongName" SG_ 930 AirCtrlrHVILClsdHSC1 "Air Controller High Voltage Interlock Loop Closed";
BA_ "GenSigStartValue" SG_ 930 HVDCDCHVSideVolVHSC1 1;
BA_ "GenSigLongName" SG_ 930 HVDCHVILStsHSC1 "High Voltage Direct Current High Voltage Interlock Loop Status";
BA_ "GenSigStartValue" SG_ 147 ISGSpd_h1HSC1 32768;
VAL_ 663 BMSMainRelaySts_h1HSC1 3 "Failure" 2 "Partly Closed" 1 "All Closed" 0 "All Open" ;
VAL_ 667 BMSChrgrPlugCnctnIO_h1HSC1 1 "Lamp Off" 0 "Lamp On" ;
VAL_ 667 BMSChrgStsIO_h1HSC1 1 "Lamp Off" 0 "Lamp On" ;
VAL_ 674 BMSBalcRmndngReqHSC1 1 "TRUE" 0 "FALSE" ;
VAL_ 674 BMSCellMaxTemV_h1HSC1 1 "Invalid" 0 "Valid" ;
VAL_ 674 BMSCellMinTemV_h1HSC1 1 "Invalid" 0 "Valid" ;
VAL_ 674 BMSChlrOffReqHSC1 1 "TRUE" 0 "FALSE" ;
VAL_ 674 BMSClntTemVHSC1 1 "Invalid" 0 "Valid" ;
VAL_ 674 BMSFltIndReqHSC1 2 "Flashing  Hertz Indication" 1 "Continuous Indication" 0 "No Indication" ;
VAL_ 674 BMSOdoFctVHSC1 1 "Invalid" 0 "Valid" ;
VAL_ 674 BMSOnbdChrgrPlugOn_h1HSC1 1 "TRUE" 0 "FALSE" ;
VAL_ 674 BMSPumpSts_h1HSC1 3 "Failed High" 2 "Failed Low" 1 "On" 0 "OFF" ;
VAL_ 674 ChrgrSysKeepAwkHSC1 1 "TRUE" 0 "FALSE" ;
VAL_ 674 HVBatShutOffHSC1 1 "TRUE" 0 "FALSE" ;
VAL_ 939 BMSAvlblEnrgVHSC1 1 "Invalid" 0 "Valid" ;
VAL_ 939 BMSOnbdChrgEnrgV_h1HSC1 1 "Invalid" 0 "Valid" ;
VAL_ 939 BMSOnbdChrgEnrg_h1HSC1 1048575 "Error" 1048574 "Init" ;
VAL_ 939 BMSPwrEfncyV_h1HSC1 1 "Invalid" 0 "Valid" ;
VAL_ 939 BMSPwrEfncy_h1HSC1 255 "Error" 254 "Init" ;
VAL_ 939 ElecEnrgAvgRstPerfdHSC1 1 "TRUE" 0 "FALSE" ;
VAL_ 939 HVBatElecEnrgAvgRateVHSC1 1 "Invalid" 0 "Valid" ;
VAL_ 940 BMSPackCrntV_h1HSC1 1 "Invalid" 0 "Valid" ;
VAL_ 940 BMSPackSOCDspVHSC1 1 "Invalid" 0 "Valid" ;
VAL_ 940 BMSPackSOCV_h1HSC1 1 "Invalid" 0 "Valid" ;
VAL_ 940 BMSPackVolV_h1HSC1 1 "Invalid" 0 "Valid" ;
VAL_ 913 BMSChrgCtrlDspCmdHSC1 3 "Reserved" 2 "Stop Charge" 1 "Start Charge" 0 "No Request" ;
VAL_ 913 BMSChrgSts_h1HSC1 5 "Reserved" 4 "Charge Fault" 3 "Balancing" 2 "Charge Done" 1 "Charging" 0 "None" ;
VAL_ 913 BMSReserCtrlDspCmdHSC1 3 "Reserved" 2 "Reservation Switch Off" 1 "Reservation Switch On" 0 "No Request" ;
VAL_ 915 BMSReserChrgMdDspCmd_h1HSC1 4 "Soc Based Mode" 3 "Range Based Mode" 2 "Energy Based Mode" 1 "Time Based Mode" 0 "Unavailable" ;
VAL_ 936 ChrgngRmnngTimeV_h1HSC1 1 "Invalid" 0 "Valid" ;
VAL_ 1288 BMSEmsnRltdMalfAHSC1 1 "True(MIL Requested ON)" 0 "False(MIL Requested OFF)" ;
VAL_ 201 EnRunAHSC1 1 "True" 0 "False" ;
VAL_ 404 TrShftLvrPosHSC1 15 "Lever Position Unknown" 11 "Forward Range H" 10 "Forward Range G" 9 "Forward Range F" 8 "Forward Range E" 7 "Forward Range D" 6 "Forward Range C" 5 "Forward Range B" 4 "Forward Range A" 3 "Neutral Range" 2 "Reverse Range" 1 "Park Range" 0 "Between Ranges" ;
VAL_ 404 TrShftLvrPosVHSC1 1 "Invalid" 0 "Valid" ;
VAL_ 1217 EnClntTemVHSC1 1 "Invalid" 0 "Valid" ;
VAL_ 889 ACAmbtTemVHSC1 1 "not valid" 0 "valid" ;
VAL_ 868 ACComprReqHSC1 3 "reserved" 2 "Engage" 1 "disengage" 0 "disengage immediately" ;
VAL_ 868 HVBatCoolngSysEnbdHSC1 1 "TRUE" 0 "FALSE" ;
VAL_ 779 ACComprActuHVHSC1 4095 "Error" 4094 "Init" ;
VAL_ 779 ESSPWMClntPumpStsHSC1 3 "Pump failure" 2 "Pump permanent on due to some kind of failure" 1 "Normal On" 0 "Nomarl Off" ;
VAL_ 1130 BntOpenStsHSC1 3 "Reserved" 2 "Bonnet Switch Disconnect" 1 "Bonnet Open" 0 "Bonnet Closed" ;
VAL_ 1130 VehLckngStaHSC1 7 "Unknow" 6 "Reserved" 5 "Reserved" 4 "Super locked" 3 "Exterior Locked" 2 "Interior Locked" 1 "Signal Position Entry Unlocked" 0 "Unlocked" ;
VAL_ 540 RVSReqHSC1 1 "request" 0 "no request" ;
VAL_ 498 SysBPMHSC1 3 "Crank" 2 "Run" 1 "ACC" 0 "Off" ;
VAL_ 498 SysBPMEnbdHSC1 1 "TRUE" 0 "FALSE" ;
VAL_ 886 RstrFctryDeftsReqHSC1 1 "TRUE" 0 "FALSE" ;
VAL_ 847 FICMChrgCtrlReqHSC1 3 "Reserved" 2 "Stop Charge" 1 "Start Charge" 0 "No Request" ;
VAL_ 847 FICMReserChrgEnrgVHSC1 1 "Invalid" 0 "Valid" ;
VAL_ 847 FICMReserChrgMdReqHSC1 4 "Soc Based Mode" 3 "Range Based Mode" 2 "Energy Based Mode" 1 "Time Based Mode" 0 "No Request" ;
VAL_ 847 FICMReserChrgRngVHSC1 1 "Invalid" 0 "Valid" ;
VAL_ 847 FICMReserCtrlReqHSC1 3 "Reserved" 2 "Reservation Switch Off" 1 "Reservation Switch On" 0 "No Request" ;
VAL_ 847 FICMReserDurtnTimeVHSC1 1 "Invalid" 0 "Valid" ;
VAL_ 847 FICMReserMaxCrntVHSC1 1 "Invalid" 0 "Valid" ;
VAL_ 847 FICMReserStTimeVHSC1 1 "Invalid" 0 "Valid" ;
VAL_ 847 FICMReserTgtSOCVHSC1 1 "Invalid" 0 "Valid" ;
VAL_ 361 ACAvlbly_h1HSC1 1 "TRUE" 0 "FALSE" ;
VAL_ 361 BCMAvlbly_h1HSC1 1 "TRUE" 0 "FALSE" ;
VAL_ 361 IPCAvlbly_h1HSC1 1 "TRUE" 0 "FALSE" ;
VAL_ 361 SCSAvlbly_h1HSC1 1 "TRUE" 0 "FALSE" ;
VAL_ 497 PwrMdMstrAccryA_h1HSC1 1 "Active" 0 "Inactive" ;
VAL_ 497 PwrMdMstrRunCrkA_h1HSC1 1 "Active" 0 "Inactive" ;
VAL_ 497 SysOpnlMd_h1HSC1 5 "Diagnosic or Reprogramming(Reserve)" 4 "Storage" 3 "Show Room(Reserve)" 2 "End of Line(Reserve)" 1 "Assembly" 0 "Normal Mode" ;
VAL_ 497 SysPwrMd_h1HSC1 3 "Crank" 2 "Run" 1 "ACC" 0 "Off" ;
VAL_ 497 SysVolMdV_h1HSC1 1 "Invalid" 0 "Valid" ;
VAL_ 497 SysVolMd_h1HSC1 3 "Illegal System  Voltage" 2 "High System Voltage" 1 "Low System Voltage" 0 "Normal" ;
VAL_ 497 SysVolV_h1HSC1 1 "Invalid" 0 "Valid" ;
VAL_ 1344 VehOdoV_h1HSC1 1 "Invalid" 0 "Valid" ;
VAL_ 1009 OtsdAirTemCrValV_h1HSC1 1 "Invalid" 0 "Valid" ;
VAL_ 1345 CalendarMonthHSC1 15 "Reserved" 14 "Reserved" 13 "Reserved" 12 "December" 11 "November" 10 "October" 9 "September" 8 "August" 7 "July" 6 "June" 5 "May" 4 "April" 3 "March" 2 "February" 1 "January" 0 "Unknown" ;
VAL_ 835 ElecEnrgAvgRstReqHSC1 1 "TRUE" 0 "FALSE" ;
VAL_ 175 EPTAccelActuPosVHSC1 1 "Invalid" 0 "Valid" ;
VAL_ 175 EPTBrkPdlDscrtInptStsHSC1 1 "Brake Applied" 0 "Brake Not Applied" ;
VAL_ 175 EPTBrkPdlDscrtInptStsVHSC1 1 "Invalid" 0 "Valid" ;
VAL_ 175 EPTStCmdOnHSC1 1 "TRUE" 0 "FALSE" ;
VAL_ 406 EPTRdyHSC1 1 "ready" 0 "not ready" ;
VAL_ 907 ElecVehSysMdHSC1 15 "Reserved" 14 "Reserved" 13 "Reserved" 12 "Reserved" 11 "Reserved" 10 "Reserved" 9 "Reserved" 8 "PlugIn Charging" 7 "Regen brake mode" 6 "Parallel drive mode" 5 "Series drive mode" 4 "Pure engine drive mode" 3 "Pure electric drive mode" 2 "Smart charge" 1 "Idle charge" 0 "default" ;
VAL_ 907 EPTDrvngMdSwStsHSC1 7 "Reserved" 6 "Reserved" 5 "Reserved" 4 "C-Charge" 3 "H-SOC Hold" 2 "M - Mountain(Sport)" 1 "N - Normal" 0 "E - Economy" ;
VAL_ 930 AirCtrlrHVILClsdHSC1 2 "Fault" 1 "Normal" 0 "Initial" ;
VAL_ 930 HVDCDCHVSideVolVHSC1 1 "Invalid" 0 "Valid" ;
VAL_ 930 HVDCHVILStsHSC1 2 "Fault" 1 "Normal" 0 "Initial" ;
VAL_ 851 VehSpdAvgDrvnV_h1HSC1 1 "Invalid" 0 "Valid" ;
VAL_ 355 AirbagDplHSC1 1 "TRUE" 0 "FALSE" ;
